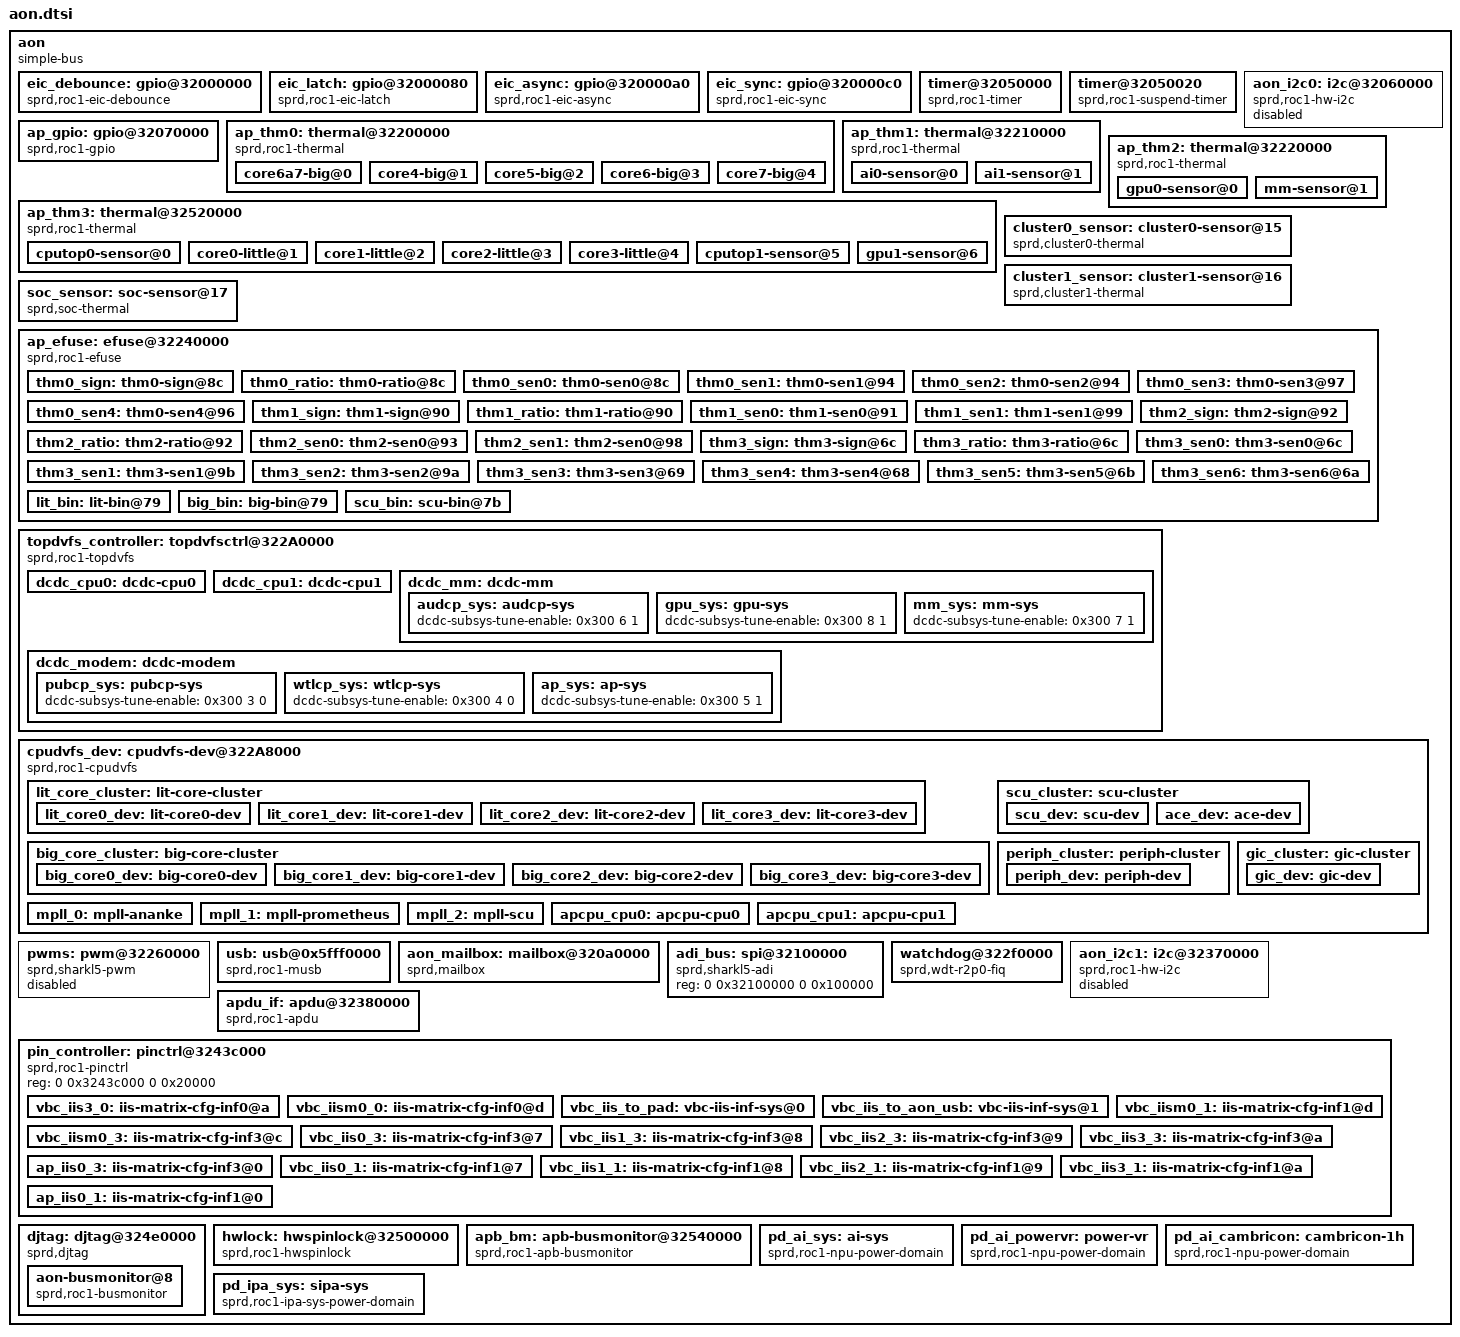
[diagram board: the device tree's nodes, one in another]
/*
 * Spreadtrum Roc1 platform DTS file
 *
 * Copyright (C) 2018, Spreadtrum Communications Inc.
 *
 * This file is licensed under a dual GPLv2 or X11 license.
 */

		aon {
			compatible = "simple-bus";
			#address-cells = <2>;
			#size-cells = <2>;
			ranges;

			eic_debounce: gpio@32000000 {
				compatible = "sprd,roc1-eic-debounce";
				reg = <0 0x32000000 0 0x80>,
				      <0 0x32010000 0 0x80>,
				      <0 0x32020000 0 0x80>,
				      <0 0x32030000 0 0x80>,
				      <0 0x32230000 0 0x80>,
				      <0 0x32270000 0 0x80>;
				gpio-controller;
				#gpio-cells = <2>;
				interrupt-controller;
				#interrupt-cells = <2>;
				interrupts = <GIC_SPI 72 IRQ_TYPE_LEVEL_HIGH>;
			};

			eic_latch: gpio@32000080 {
				compatible = "sprd,roc1-eic-latch";
				reg = <0 0x32000080 0 0x20>,
				      <0 0x32010080 0 0x20>,
				      <0 0x32020080 0 0x20>,
				      <0 0x32030080 0 0x20>,
				      <0 0x32230080 0 0x20>,
				      <0 0x32270080 0 0x20>;
				gpio-controller;
				#gpio-cells = <2>;
				interrupt-controller;
				#interrupt-cells = <2>;
				interrupts = <GIC_SPI 72 IRQ_TYPE_LEVEL_HIGH>;
			};

			eic_async: gpio@320000a0 {
				compatible = "sprd,roc1-eic-async";
				reg = <0 0x320000a0 0 0x20>,
				      <0 0x320100a0 0 0x20>,
				      <0 0x320200a0 0 0x20>,
				      <0 0x320300a0 0 0x20>,
				      <0 0x322300a0 0 0x20>,
				      <0 0x322700a0 0 0x20>;
				gpio-controller;
				#gpio-cells = <2>;
				interrupt-controller;
				#interrupt-cells = <2>;
				interrupts = <GIC_SPI 72 IRQ_TYPE_LEVEL_HIGH>;
			};

			eic_sync: gpio@320000c0 {
				compatible = "sprd,roc1-eic-sync";
				reg = <0 0x320000c0 0 0x20>,
				      <0 0x320100c0 0 0x20>,
				      <0 0x320200c0 0 0x20>,
				      <0 0x320300c0 0 0x20>,
				      <0 0x322300c0 0 0x20>,
				      <0 0x322700c0 0 0x20>;
				gpio-controller;
				#gpio-cells = <2>;
				interrupt-controller;
				#interrupt-cells = <2>;
				interrupts = <GIC_SPI 72 IRQ_TYPE_LEVEL_HIGH>;
			};

			timer@32050000 {
				compatible = "sprd,roc1-timer";
				reg = <0 0x32050000 0 0x20>;
				interrupts = <GIC_SPI 71 IRQ_TYPE_LEVEL_HIGH>;
				clocks = <&ext_32k>;
			};

			timer@32050020 {
				compatible = "sprd,roc1-suspend-timer";
				reg = <0 0x32050020 0 0x20>;
				clocks = <&ext_32k>;
			};

			aon_i2c0: i2c@32060000 {
				compatible = "sprd,roc1-hw-i2c";
				reg = <0 0x32060000 0 0x1000>;
				interrupts = <GIC_SPI 68 IRQ_TYPE_LEVEL_HIGH>;
				clock-names = "source", "enable", "i2c",
						"clk_hw_i2c";
				clock-frequency = <400000>;
				#address-cells = <1>;
				#size-cells = <0>;
				status = "disabled";
			};

			ap_gpio: gpio@32070000 {
				compatible = "sprd,roc1-gpio";
				reg = <0 0x32070000 0 0x10000>;
				gpio-controller;
				#gpio-cells = <2>;
				interrupt-controller;
				#interrupt-cells = <2>;
				interrupts = <GIC_SPI 61 IRQ_TYPE_LEVEL_HIGH>;
			};

			ap_thm0: thermal@32200000 {
				compatible = "sprd,roc1-thermal";
				reg = <0 0x32200000 0 0x10000>;
				clock-names = "enable";
				clocks = <&aonapb_gate CLK_THM0_EB>;
				#thermal-sensor-cells = <1>;
				nvmem-cells = <&thm0_sign>, <&thm0_ratio>;
				nvmem-cell-names = "thm_sign_cal", "thm_ratio_cal";

				core6a7-big@0{
					reg = <0>;
					nvmem-cells = <&thm0_sen0>;
					nvmem-cell-names = "sen_delta_cal";
				};

				core4-big@1{
					reg = <1>;
					nvmem-cells = <&thm0_sen1>;
					nvmem-cell-names = "sen_delta_cal";
				};

				core5-big@2{
					reg = <2>;
					nvmem-cells = <&thm0_sen2>;
					nvmem-cell-names = "sen_delta_cal";
				};

				core6-big@3{
					reg = <3>;
					nvmem-cells = <&thm0_sen3>;
					nvmem-cell-names = "sen_delta_cal";
				};

				core7-big@4{
					reg = <4>;
					nvmem-cells = <&thm0_sen4>;
					nvmem-cell-names = "sen_delta_cal";
				};
			};

			ap_thm1: thermal@32210000 {
				compatible = "sprd,roc1-thermal";
				reg = <0 0x32210000 0 0x10000>;
				clock-names = "enable";
				clocks = <&aonapb_gate CLK_THM1_EB>;
				#thermal-sensor-cells = <1>;
				nvmem-cells = <&thm1_sign>, <&thm1_ratio>;
				nvmem-cell-names = "thm_sign_cal", "thm_ratio_cal";

				ai0-sensor@0{
					reg = <0>;
					nvmem-cells = <&thm1_sen0>;
					nvmem-cell-names = "sen_delta_cal";
				};

				ai1-sensor@1{
					reg = <1>;
					nvmem-cells = <&thm1_sen1>;
					nvmem-cell-names = "sen_delta_cal";
				};
			};

			ap_thm2: thermal@32220000 {
				compatible = "sprd,roc1-thermal";
				reg = <0 0x32220000 0 0x10000>;
				clock-names = "enable";
				clocks = <&aonapb_gate CLK_THM2_EB>;
				#thermal-sensor-cells = <1>;
				nvmem-cells = <&thm2_sign>, <&thm2_ratio>;
				nvmem-cell-names = "thm_sign_cal", "thm_ratio_cal";

				gpu0-sensor@0{
					reg = <0>;
					nvmem-cells = <&thm2_sen0>;
					nvmem-cell-names = "sen_delta_cal";
				};

				mm-sensor@1{
					reg = <1>;
					nvmem-cells = <&thm2_sen1>;
					nvmem-cell-names = "sen_delta_cal";
				};
			};

			ap_thm3: thermal@32520000 {
				compatible = "sprd,roc1-thermal";
				reg = <0 0x32520000 0 0x10000>;
				clock-names = "enable";
				clocks = <&aonapb_gate CLK_THM3_EB>;
				#thermal-sensor-cells = <1>;
				nvmem-cells = <&thm3_sign>, <&thm3_ratio>;
				nvmem-cell-names = "thm_sign_cal", "thm_ratio_cal";

				cputop0-sensor@0{
					reg = <0>;
					nvmem-cells = <&thm3_sen0>;
					nvmem-cell-names = "sen_delta_cal";
				};

				core0-little@1{
					reg = <1>;
					nvmem-cells = <&thm3_sen1>;
					nvmem-cell-names = "sen_delta_cal";
				};

				core1-little@2{
					reg = <2>;
					nvmem-cells = <&thm3_sen2>;
					nvmem-cell-names = "sen_delta_cal";
				};

				core2-little@3{
					reg = <3>;
					nvmem-cells = <&thm3_sen3>;
					nvmem-cell-names = "sen_delta_cal";
				};

				core3-little@4{
					reg = <4>;
					nvmem-cells = <&thm3_sen4>;
					nvmem-cell-names = "sen_delta_cal";
				};

				cputop1-sensor@5{
					reg = <5>;
					nvmem-cells = <&thm3_sen5>;
					nvmem-cell-names = "sen_delta_cal";
				};

				gpu1-sensor@6{
					reg = <6>;
					nvmem-cells = <&thm3_sen6>;
					nvmem-cell-names = "sen_delta_cal";
				};
			};

			cluster0_sensor: cluster0-sensor@15 {
				compatible = "sprd,cluster0-thermal";
				#thermal-sensor-cells = <1>;
				sensor-names = "littlecore0-thmzone",
					"littlecore1-thmzone",
					"littlecore2-thmzone",
					"littlecore3-thmzone";
				k-po = <128>;
				k-pu = <256>;
				k-i = <2>;
				k-d = <0>;
				cutoff = <10000>;
			};

			cluster1_sensor: cluster1-sensor@16 {
				compatible = "sprd,cluster1-thermal";
				#thermal-sensor-cells = <1>;
				sensor-names = "bigcore4-thmzone",
					"bigcore5-thmzone",
					"bigcore6-thmzone",
					"bigcore7-thmzone";
				k-po = <128>;
				k-pu = <256>;
				k-i = <2>;
				k-d = <0>;
				cutoff = <10000>;
			};

			soc_sensor: soc-sensor@17 {
				compatible = "sprd,soc-thermal";
				#thermal-sensor-cells = <1>;
				sensor-names = "cluster0-thmzone",
					"cluster1-thmzone";
				k-po = <0>;
				k-pu = <0>;
				k-i = <2>;
				k-d = <0>;
				cutoff = <0>;
			};

			ap_efuse: efuse@32240000 {
				compatible = "sprd,roc1-efuse";
				reg = <0 0x32240000 0 0x10000>;
				clock-names = "enable";
				hwlocks = <&hwlock 8>;
				clocks = <&aonapb_gate CLK_EFUSE_EB>;

				thm0_sign: thm0-sign@8c{
					reg = <0x8c 0x4>;
					bits = <0 1>;
				};

				thm0_ratio: thm0-ratio@8c{
					reg = <0x8c 0x4>;
					bits = <1 7>;
				};

				thm0_sen0: thm0-sen0@8c{
					reg = <0x8d 0x4>;
					bits = <0 8>;
				};

				thm0_sen1: thm0-sen1@94{
					reg = <0x95 0x4>;
					bits = <0 8>;
				};

				thm0_sen2: thm0-sen2@94{
					reg = <0x94 0x4>;
					bits = <0 8>;
				};

				thm0_sen3: thm0-sen3@97{
					reg = <0x97 0x4>;
					bits = <0 8>;
				};

				thm0_sen4: thm0-sen4@96{
					reg = <0x96 0x4>;
					bits = <0 8>;
				};

				thm1_sign: thm1-sign@90{
					reg = <0x90 0x4>;
					bits = <0 1>;
				};

				thm1_ratio: thm1-ratio@90{
					reg = <0x90 0x4>;
					bits = <1 7>;
				};

				thm1_sen0: thm1-sen0@91{
					reg = <0x91 0x4>;
					bits = <0 8>;
				};

				thm1_sen1: thm1-sen1@99{
					reg = <0x99 0x4>;
					bits = <0 8>;
				};

				thm2_sign: thm2-sign@92{
					reg = <0x92 0x4>;
					bits = <0 1>;
				};

				thm2_ratio: thm2-ratio@92{
					reg = <0x92 0x4>;
					bits = <1 7>;
				};

				thm2_sen0: thm2-sen0@93{
					reg = <0x93 0x4>;
					bits = <0 8>;
				};

				thm2_sen1: thm2-sen0@98{
					reg = <0x98 0x4>;
					bits = <0 8>;
				};

				thm3_sign: thm3-sign@6c{
					reg = <0x6c 0x4>;
					bits = <0 1>;
				};

				thm3_ratio: thm3-ratio@6c{
					reg = <0x6c 0x4>;
					bits = <1 7>;
				};

				thm3_sen0: thm3-sen0@6c{
					reg = <0x6d 0x4>;
					bits = <0 8>;
				};

				thm3_sen1: thm3-sen1@9b{
					reg = <0x9b 0x4>;
					bits = <0 8>;
				};

				thm3_sen2: thm3-sen2@9a{
					reg = <0x9a 0x4>;
					bits = <0 8>;
				};

				thm3_sen3: thm3-sen3@69{
					reg = <0x69 0x4>;
					bits = <0 8>;
				};

				thm3_sen4: thm3-sen4@68{
					reg = <0x68 0x4>;
					bits = <0 8>;
				};

				thm3_sen5: thm3-sen5@6b{
					reg = <0x6b 0x4>;
					bits = <0 8>;
				};

				thm3_sen6: thm3-sen6@6a{
					reg = <0x6a 0x4>;
					bits = <0 8>;
				};

				lit_bin: lit-bin@79{
					reg = <0x79 0x1>;
					bits = <0 4>;
				};

				big_bin: big-bin@79{
					reg = <0x79 0x1>;
					bits = <4 4>;
				};

				scu_bin: scu-bin@7b{
					reg = <0x7b 0x1>;
					bits = <4 4>;
				};
			};

			topdvfs_controller: topdvfsctrl@322A0000 {
				compatible = "sprd,roc1-topdvfs", "syscon";
				sprd,syscon-enable = <&aon_apb_regs>;
				module-enable-cfg = <0x4 7>;
				reg = <0 0x322A0000 0 0x8000>;
				cpu-dcdc-cells = <&dcdc_cpu0>, <&dcdc_cpu1>;
				device-dcdc-cells = <&dcdc_mm>, <&dcdc_modem>;
				dcdc_cpu0: dcdc-cpu0{
					dcdc-dvfs-enable = <0x90 0 1>;
					dcdc-judge-vol-sw = <0x150 15 0x7 0>;
					dcdc-subsys-tune-enable = <0x300 2 1>;
					dcdc-supply-mode-cfg = <&dvfs_dcdc_cpu0_supply>;
					sync-dcdc-idle-voltage;
					dcdc-idle-voltage = <0x320 6 0x7 5>;
				};
				dcdc_cpu1: dcdc-cpu1{
					dcdc-dvfs-enable = <0xA0 0 1>;
					dcdc-judge-vol-sw = <0x160 15 0x7 0>;
					dcdc-subsys-tune-enable = <0x300 1 1>;
					dcdc-supply-mode-cfg = <&dvfs_dcdc_cpu1_supply>;
					sync-dcdc-idle-voltage;
					dcdc-idle-voltage = <0x320 3 0x7 5>;
				};
				dcdc_mm: dcdc-mm {
					dcdc-dvfs-enable = <0x18 20 1>;
					dcdc-judge-vol-sw = <0x18 1 0x7 2>;
					dcdc-subsys-cells = <&audcp_sys>,
							<&gpu_sys>,
							<&mm_sys>;
					audcp_sys: audcp-sys {
						dcdc-subsys-tune-enable = <0x300 6 1>;
					};
					gpu_sys: gpu-sys {
						dcdc-subsys-tune-enable = <0x300 8 1>;
					};

					mm_sys: mm-sys {
						dcdc-subsys-tune-enable = <0x300 7 1>;
					};
				};
				dcdc_modem: dcdc-modem {
					dcdc-dvfs-enable = <0x48 20 1>;
					dcdc-judge-vol-sw = <0x48 1 0x7 2>;
					dcdc-subsys-cells = <&pubcp_sys>,
							<&wtlcp_sys>,
							<&ap_sys>;
					pubcp_sys: pubcp-sys {
						dcdc-subsys-tune-enable = <0x300 3 0>;
					};
					wtlcp_sys: wtlcp-sys {
						dcdc-subsys-tune-enable = <0x300 4 0>;
					};
					ap_sys: ap-sys {
						dcdc-subsys-tune-enable = <0x300 5 1>;
					};
				};
			};

			cpudvfs_dev: cpudvfs-dev@322A8000 {
				compatible = "sprd,roc1-cpudvfs";
				sprd,syscon-enable = <&aon_apb_regs>;
				module-enable-cfg = <0x4 7>;
				topdvfs-controller = <&topdvfs_controller>;
				reg = <0 0x322A8000 0 0x1000>;
				mpll-cells = <&mpll_0>, <&mpll_1>, <&mpll_2>;
				apcpu-dvfs-dcdc-cells = <&apcpu_cpu0>,
						<&apcpu_cpu1>;
				cpudvfs-clusters = <&lit_core_cluster>,
						<&big_core_cluster>,
						<&scu_cluster>,
						<&periph_cluster>,
						<&gic_cluster>;
				lit_core_cluster: lit-core-cluster {
					cluster-name = "lit-core-cluster";
					row-num = <16>;
					column-num = <7>;
					work-index-cfg = <0x214 0xF>;
					idle-index-cfg = <0x218 0xF>;
					tuning-latency-us = <200>;
					tuning-result-judge = <0>;
					dcdc-name = "DCDC_CPU0";
					map-tbl-regs = <0x60 0x64 0x68 0x6C 0x70 0x74 0x78 0x7C 0x80 0x84 0x88 0x8C 0x90 0x94 0x98 0x9C>;
					column-entry-start-bit = <0 2 15 5 9 18 12>;
					column-entry-mask = <0x3 0x7 0x7 0xF 0x7 0x7 0x7>;
					cluster-devices = <&lit_core0_dev>,
							<&lit_core1_dev>,
							<&lit_core2_dev>,
							<&lit_core3_dev>;
					lit-core-dvfs-tbl = < /* od */
							/* sel div gear scu periph gic mpll */
							0 0 0 0 0 0 0
							2 1 0 1 1 1 0
							1 0 0 1 1 1 0
							3 0 1 2 1 1 0
							3 0 2 3 2 2 1
							2 0 3 4 2 2 0
							3 0 4 5 2 3 2
							3 0 5 6 2 3 3
							3 0 6 7 2 3 4
							3 0 7 8 2 3 5
							3 0 7 8 2 3 5
							3 0 7 8 2 3 5
							3 0 7 8 2 3 5
							3 0 7 8 2 3 5
							3 0 7 8 2 3 5
							3 0 7 8 2 3 5
							>;
					lit-core-dvfs-tbl-1 = <
							/* sel div gear scu periph gic mpll */
							0 0 0 0 0 0 0
							2 1 0 1 1 1 0
							1 0 0 1 1 1 0
							3 0 0 2 1 1 0
							3 0 0 3 2 2 1
							2 0 1 4 2 2 0
							3 0 2 5 2 3 2
							3 0 3 6 2 3 3
							3 0 4 7 2 3 4
							3 0 5 8 2 3 5
							3 0 5 8 2 3 5
							3 0 5 8 2 3 5
							3 0 5 8 2 3 5
							3 0 5 8 2 3 5
							3 0 5 8 2 3 5
							3 0 5 8 2 3 5
							>;
					lit-core-dvfs-tbl-2 = <
							/* sel div gear scu periph gic mpll */
							0 0 0 0 0 0 0
							2 1 0 1 1 1 0
							1 0 0 1 1 1 0
							3 0 0 2 1 1 0
							3 0 1 3 2 2 1
							2 0 2 4 2 2 0
							3 0 3 5 2 3 2
							3 0 4 6 2 3 3
							3 0 5 7 2 3 4
							3 0 6 8 2 3 5
							3 0 6 8 2 3 5
							3 0 6 8 2 3 5
							3 0 6 8 2 3 5
							3 0 6 8 2 3 5
							3 0 6 8 2 3 5
							3 0 6 8 2 3 5
							>;
					lit-core-dvfs-tbl-3 = <
							/* sel div gear scu periph gic mpll */
							0 0 0 0 0 0 0
							2 1 0 1 1 1 0
							1 0 0 1 1 1 0
							3 0 0 2 1 1 0
							3 0 1 3 2 2 1
							2 0 2 4 2 2 0
							3 0 3 5 2 3 2
							3 0 4 6 2 3 3
							3 0 5 7 2 3 4
							3 0 6 8 2 3 5
							3 0 6 8 2 3 5
							3 0 6 8 2 3 5
							3 0 6 8 2 3 5
							3 0 6 8 2 3 5
							3 0 6 8 2 3 5
							3 0 6 8 2 3 5
							>;
					lit-core-dvfs-tbl-4 = <
							/* sel div gear scu periph gic mpll */
							0 0 0 0 0 0 0
							2 1 0 1 1 1 0
							1 0 0 1 1 1 0
							3 0 1 2 1 1 0
							3 0 2 3 2 2 1
							2 0 3 4 2 2 0
							3 0 4 5 2 3 2
							3 0 5 6 2 3 3
							3 0 6 7 2 3 4
							3 0 7 8 2 3 5
							3 0 7 8 2 3 5
							3 0 7 8 2 3 5
							3 0 7 8 2 3 5
							3 0 7 8 2 3 5
							3 0 7 8 2 3 5
							3 0 7 8 2 3 5
							>;
					lit_core0_dev: lit-core0-dev {
						device-name = "cpu0";
						sel-get = <0x38 0 3>;
						div-get = <0x38 2 7>;
						vol-get = <0x30 0 7>;
						dfs-idle-disable = <0x308 0 1>;
					};
					lit_core1_dev: lit-core1-dev {
						device-name = "cpu1";
						sel-get = <0x38 5 3>;
						div-get = <0x38 7 7>;
						vol-get = <0x30 3 7>;
						dfs-idle-disable = <0x308 1 1>;
					};
					lit_core2_dev: lit-core2-dev {
						device-name = "cpu2";
						sel-get = <0x38 10 3>;
						div-get = <0x38 12 7>;
						vol-get = <0x30 6 7>;
						dfs-idle-disable = <0x308 2 1>;
					};
					lit_core3_dev: lit-core3-dev {
						device-name = "cpu3";
						sel-get = <0x38 15 3>;
						div-get = <0x38 17 7>;
						vol-get = <0x30 9 7>;
						dfs-idle-disable = <0x308 3 1>;
					};
				};
				big_core_cluster: big-core-cluster {
					cluster-name = "big-core-cluster";
					row-num = <16>;
					column-num = <8>;
					work-index-cfg = <0x224 0xF>;
					idle-index-cfg = <0x228 0xF>;
					tuning-latency-us = <200>;
					tuning-result-judge = <0>;
					dcdc-name = "DCDC_CPU1";
					map-tbl-regs = <0xA0 0xA4 0xA8 0xAC 0xB0 0xB4 0xB8 0xBC 0xC0 0xC4 0xC8 0xCC 0xD0 0xD4 0xD8 0xDC>;
					column-entry-start-bit = <0 2 15 5 9 18 12 21>;
					column-entry-mask = <0x3 0x7 0x7 0xF 0x7 0x7 0x7 0x7>;
					cluster-devices = <&big_core0_dev>,
							<&big_core1_dev>,
							<&big_core2_dev>,
							<&big_core3_dev>;
					big-core-dvfs-tbl = < /* od */
							/* sel div gear scu periph cpu0 mpll gic */
							0 0 0 0 0 0 0 0
							1 0 0 3 2 0 0 2
							3 0 1 5 2 0 0 3
							3 0 2 7 2 0 1 3
							3 0 3 8 2 0 2 3
							3 0 4 8 2 0 3 3
							3 0 5 8 2 0 4 3
							3 0 5 8 2 0 4 3
							3 0 5 8 2 0 4 3
							3 0 5 8 2 0 4 3
							3 0 5 8 2 0 4 3
							3 0 5 8 2 0 4 3
							3 0 5 8 2 0 4 3
							3 0 5 8 2 0 4 3
							3 0 5 8 2 0 4 3
							3 0 5 8 2 0 4 3
							>;
					big-core-dvfs-tbl-1 = <
							/* sel div gear scu periph cpu0 mpll gic */
							0 0 0 0 0 0 0 0
							1 0 0 3 2 0 0 2
							3 0 1 5 2 0 0 3
							3 0 2 7 2 0 1 3
							3 0 3 8 2 0 2 3
							3 0 4 8 2 0 3 3
							3 0 5 8 2 0 4 3
							3 0 5 8 2 0 4 3
							3 0 5 8 2 0 4 3
							3 0 5 8 2 0 4 3
							3 0 5 8 2 0 4 3
							3 0 5 8 2 0 4 3
							3 0 5 8 2 0 4 3
							3 0 5 8 2 0 4 3
							3 0 5 8 2 0 4 3
							3 0 5 8 2 0 4 3
							>;
					big-core-dvfs-tbl-2 = <
							/* sel div gear scu periph cpu0 mpll gic */
							0 0 0 0 0 0 0 0
							1 0 0 3 2 0 0 2
							3 0 1 5 2 0 0 3
							3 0 2 7 2 0 1 3
							3 0 3 8 2 0 2 3
							3 0 4 8 2 0 3 3
							3 0 5 8 2 0 4 3
							3 0 5 8 2 0 4 3
							3 0 5 8 2 0 4 3
							3 0 5 8 2 0 4 3
							3 0 5 8 2 0 4 3
							3 0 5 8 2 0 4 3
							3 0 5 8 2 0 4 3
							3 0 5 8 2 0 4 3
							3 0 5 8 2 0 4 3
							3 0 5 8 2 0 4 3
							>;
					big-core-dvfs-tbl-3 = <
							/* sel div gear scu periph cpu0 mpll gic */
							0 0 0 0 0 0 0 0
							1 0 0 3 2 0 0 2
							3 0 1 5 2 0 0 3
							3 0 2 7 2 0 1 3
							3 0 3 8 2 0 2 3
							3 0 4 8 2 0 3 3
							3 0 5 8 2 0 4 3
							3 0 5 8 2 0 4 3
							3 0 5 8 2 0 4 3
							3 0 5 8 2 0 4 3
							3 0 5 8 2 0 4 3
							3 0 5 8 2 0 4 3
							3 0 5 8 2 0 4 3
							3 0 5 8 2 0 4 3
							3 0 5 8 2 0 4 3
							3 0 5 8 2 0 4 3
							>;
					big-core-dvfs-tbl-4 = <
							/* sel div gear scu periph cpu0 mpll gic */
							0 0 0 0 0 0 0 0
							1 0 0 3 2 0 0 2
							3 0 1 5 2 0 0 3
							3 0 2 7 2 0 1 3
							3 0 3 8 2 0 2 3
							3 0 4 8 2 0 3 3
							3 0 5 8 2 0 4 3
							3 0 5 8 2 0 4 3
							3 0 5 8 2 0 4 3
							3 0 5 8 2 0 4 3
							3 0 5 8 2 0 4 3
							3 0 5 8 2 0 4 3
							3 0 5 8 2 0 4 3
							3 0 5 8 2 0 4 3
							3 0 5 8 2 0 4 3
							3 0 5 8 2 0 4 3
							>;
					big_core0_dev: big-core0-dev {
						device-name = "cpu4";
						sel-get = <0x38 20 3>;
						div-get = <0x38 22 7>;
						vol-get = <0x30 12 7>;
						dfs-idle-disable = <0x308 4 1>;
					};
					big_core1_dev: big-core1-dev {
						device-name = "cpu5";
						sel-get = <0x38 25 3>;
						div-get = <0x38 27 7>;
						vol-get = <0x30 15 7>;
						dfs-idle-disable = <0x308 5 1>;
					};
					big_core2_dev: big-core2-dev {
						device-name = "cpu6";
						sel-get = <0x3C 0 3>;
						div-get = <0x3C 2 7>;
						vol-get = <0x30 18 7>;
						dfs-idle-disable = <0x308 6 1>;
					};
					big_core3_dev: big-core3-dev {
						device-name = "cpu7";
						sel-get = <0x3C 5 3>;
						div-get = <0x3C 7 7>;
						vol-get = <0x30 21 7>;
						dfs-idle-disable = <0x308 7 1>;
					};
				};
				scu_cluster: scu-cluster {
					cluster-name = "scu-cluster";
					row-num = <16>;
					column-num = <5>;
					work-index-cfg = <0x22C 0xF>;
					idle-index-cfg = <0x230 0xF>;
					dcdc-name = "DCDC_CPU0";
					tuning-func-cfg = <0x18 1>;
					map-tbl-regs = <0x180 0x184 0x188 0x18C 0x190 0x194 0x198 0x19C 0x1A0 0x1A4 0x1A8 0x1AC 0x1B0 0x1B4 0x1B8 0x1BC>;
					column-entry-start-bit = <0 3 12 6 9>;
					column-entry-mask = <0x7 0x7 0x7 0x7 0x7>;
					cluster-devices = <&scu_dev>, <&ace_dev>;
					scu-dvfs-tbl = <
							/* sel div gear ace mpll */
							0 0 0 0 0
							4 0 0 1 0
							4 0 1 1 1
							1 0 2 1 0
							4 0 3 1 2
							4 0 4 1 3
							4 0 5 1 3
							4 0 6 1 4
							4 0 7 1 5
							4 0 7 1 5
							4 0 7 1 5
							4 0 7 1 5
							4 0 7 1 5
							4 0 7 1 5
							4 0 7 1 5
							4 0 7 1 5
							>;
					scu-dvfs-tbl-1 = <
							/* sel div gear ace mpll */
							0 0 0 0 0
							4 0 0 1 0
							4 0 0 1 1
							1 0 0 1 0
							4 0 1 1 2
							4 0 2 1 3
							4 0 3 1 3
							4 0 4 1 4
							4 0 5 1 5
							4 0 5 1 5
							4 0 5 1 5
							4 0 5 1 5
							4 0 5 1 5
							4 0 5 1 5
							4 0 5 1 5
							4 0 5 1 5
							>;
					scu-dvfs-tbl-2 = <
							/* sel div gear ace mpll */
							0 0 0 0 0
							4 0 0 1 0
							4 0 0 1 1
							1 0 1 1 0
							4 0 2 1 2
							4 0 3 1 3
							4 0 4 1 3
							4 0 5 1 4
							4 0 6 1 5
							4 0 6 1 5
							4 0 6 1 5
							4 0 6 1 5
							4 0 6 1 5
							4 0 6 1 5
							4 0 6 1 5
							4 0 6 1 5
							>;
					scu-dvfs-tbl-3 = <
							/* sel div gear ace mpll */
							0 0 0 0 0
							4 0 0 1 0
							4 0 0 1 1
							1 0 1 1 0
							4 0 2 1 2
							4 0 3 1 3
							4 0 4 1 3
							4 0 5 1 4
							4 0 6 1 5
							4 0 6 1 5
							4 0 6 1 5
							4 0 6 1 5
							4 0 6 1 5
							4 0 6 1 5
							4 0 6 1 5
							4 0 6 1 5
							>;
					scu-dvfs-tbl-4 = <
							/* sel div gear ace mpll */
							0 0 0 0 0
							4 0 0 1 0
							4 0 1 1 1
							1 0 2 1 0
							4 0 3 1 2
							4 0 4 1 3
							4 0 5 1 3
							4 0 6 1 4
							4 0 7 1 5
							4 0 7 1 5
							4 0 7 1 5
							4 0 7 1 5
							4 0 7 1 5
							4 0 7 1 5
							4 0 7 1 5
							4 0 7 1 5
							>;
					scu_dev: scu-dev {
						device-name = "scu";
						sel-get = <0x3C 10 7>;
						div-get = <0x3C 13 7>;
						vol-get = <0x34 0 7>;
						dfs-idle-disable = <0x308 8 1>;
					};
					ace_dev: ace-dev {
						device-name = "ace";
						sel-get = <0x3C 10 7>;
						div-get = <0x3C 16 7>;
						vol-get = <0x34 0 7>;
					};
				};
				periph_cluster: periph-cluster {
					cluster-name = "periph-cluster";
					row-num = <8>;
					column-num = <3>;
					work-index-cfg = <0x23C 0x7>;
					idle-index-cfg = <0x240 0x7>;
					dcdc-name = "DCDC_CPU0";
					tuning-func-cfg = <0x18 0>;
					map-tbl-regs = <0x1F4 0x1F8 0x1FC 0x200 0x204 0x208 0x20C 0x210>;
					column-entry-start-bit = <0 2 5>;
					column-entry-mask = <0x3 0x7 0x7>;
					cluster-devices = <&periph_dev>;
					periph-dvfs-tbl = <
							/* sel div vol */
							0 0 0
							1 0 0
							2 1 2
							2 1 2
							2 1 2
							2 1 2
							2 1 2
							2 1 2
							>;
					periph-dvfs-tbl-1 = <
							/* sel div vol */
							0 0 0
							1 0 0
							2 1 0
							2 1 0
							2 1 0
							2 1 0
							2 1 0
							2 1 0
							>;
					periph-dvfs-tbl-2 = <
							/* sel div vol */
							0 0 0
							1 0 0
							2 1 1
							2 1 1
							2 1 1
							2 1 1
							2 1 1
							2 1 1
							>;
					periph-dvfs-tbl-3 = <
							/* sel div vol */
							0 0 0
							1 0 0
							2 1 1
							2 1 1
							2 1 1
							2 1 1
							2 1 1
							2 1 1
							>;
					periph-dvfs-tbl-4 = <
							/* sel div vol */
							0 0 0
							1 0 0
							2 1 2
							2 1 2
							2 1 2
							2 1 2
							2 1 2
							2 1 2
							>;
					periph_dev: periph-dev {
						device-name = "periph";
						sel-get = <0x3C 19 3>;
						div-get = <0x3C 21 7>;
						vol-get = <0x34 6 7>;
						dfs-idle-disable = <0x308 10 1>;
					};
				};

				gic_cluster: gic-cluster {
					cluster-name = "gic-cluster";
					row-num = <8>;
					column-num = <3>;
					work-index-cfg = <0x2E0 0x7>;
					idle-index-cfg = <0x2E4 0x7>;
					dcdc-name = "DCDC_CPU0";
					tuning-func-cfg = <0x18 2>;
					map-tbl-regs = <0x280 0x284 0x288 0x28C 0x290 0x294 0x298 0x29C>;
					column-entry-start-bit = <0 2 5>;
					column-entry-mask = <0x3 0x7 0x7>;
					cluster-devices = <&gic_dev>;
					gic-dvfs-tbl = <
							/* sel div vol */
							0 0 0
							1 0 0
							2 1 2
							3 1 4
							3 1 4
							3 1 4
							3 1 4
							3 1 4
							>;
					gic-dvfs-tbl-1 = <
							/* sel div vol */
							0 0 0
							1 0 0
							2 1 0
							3 1 2
							3 1 2
							3 1 2
							3 1 2
							3 1 2
							>;
					gic-dvfs-tbl-2 = <
							/* sel div vol */
							0 0 0
							1 0 0
							2 1 1
							3 1 3
							3 1 3
							3 1 3
							3 1 3
							3 1 3
							>;
					gic-dvfs-tbl-3 = <
							/* sel div vol */
							0 0 0
							1 0 0
							2 1 1
							3 1 3
							3 1 3
							3 1 3
							3 1 3
							3 1 3
							>;
					gic-dvfs-tbl-4 = <
							/* sel div vol */
							0 0 0
							1 0 0
							2 1 2
							3 1 4
							3 1 4
							3 1 4
							3 1 4
							3 1 4
							>;
					gic_dev: gic-dev {
						device-name = "gic";
						sel-get = <0x40 0 3>;
						div-get = <0x40 2 7>;
						vol-get = <0x34 9 7>;
						dfs-idle-disable = <0x308 11 1>;
					};
				};

				mpll_0: mpll-ananke{
					sprd,syscon-ang = <&anlg_phy_g17_regs>;
					mpll-rst = <0x44 0 1 2>;
					relock-cfg = <0x244 1>;
					pd-cfg = <0x244 0>;
				};

				mpll_1: mpll-prometheus{
					sprd,syscon-ang = <&anlg_phy_g4_regs>;
					mpll-rst = <0x40 2 4 3>;
					relock-cfg = <0x258 1>;
					pd-cfg = <0x258 0>;
				};

				mpll_2: mpll-scu{
					sprd,syscon-ang = <&anlg_phy_g9_regs>;
					mpll-rst = <0x40 0 1 2>;
					relock-cfg = <0x26C 1>;
					pd-cfg = <0x26C 0>;
				};

				apcpu_cpu0: apcpu-cpu0 {
					subsys-dcdc-vol-sw = <0x20 4 0x7 0>;
					subsys-dvfs-state = <0x44 0 7>;
				};
				apcpu_cpu1: apcpu-cpu1 {
					subsys-dcdc-vol-sw = <0x24 4 0x7 0>;
					subsys-dvfs-state = <0x4C 0 7>;
				};
			};

			pwms: pwm@32260000 {
				compatible = "sprd,sharkl5-pwm", "sprd,roc1-pwm";
				reg = <0 0x32260000 0 0x10000>;
				status = "disabled";
				clock-names = "clk_parent",
					"clk_pwm0", "clk_pwm0_eb",
					"clk_pwm1", "clk_pwm1_eb",
					"clk_pwm2", "clk_pwm2_eb",
					"clk_pwm3", "clk_pwm3_eb";
				clocks = <&ext_26m>,
					<&aon_clk CLK_AON_PWM0>,
					<&aonapb_gate CLK_PWM0_EB>,
					<&aon_clk CLK_AON_PWM1>,
					<&aonapb_gate CLK_PWM1_EB>,
					<&aon_clk CLK_AON_PWM2>,
					<&aonapb_gate CLK_PWM2_EB>,
					<&aon_clk CLK_AON_PWM3>,
					<&aonapb_gate CLK_PWM3_EB>;
				#pwm-cells = <2>;
			};

			usb: usb@0x5fff0000 {
				compatible = "sprd,roc1-musb";
				reg = <0 0x5fff0000 0 0x2000>;
				interrupts = <GIC_SPI 69 IRQ_TYPE_LEVEL_HIGH>;
				interrupt-names = "mc";
				clocks = <&aonapb_gate CLK_OTG_UTMI_EB>;
				clock-names = "core_clk";
				usb-phy = <&hsphy>;
				phy-names = "usb";
				dr-mode = "peripheral";
			};

			aon_mailbox: mailbox@320a0000 {
				compatible = "sprd,mailbox";
				reg = <0 0x320a0000 0 0x8000>,
				      <0 0x320a8000 0 0x8000>;
				syscons = <&aon_apb_regs 0x4 0x4>;
				syscon-names = "clk";
				interrupts = <GIC_SPI 82 IRQ_TYPE_LEVEL_HIGH>,
					     <GIC_SPI 83 IRQ_TYPE_LEVEL_HIGH>,
					     <GIC_SPI 84 IRQ_TYPE_LEVEL_HIGH>;
				sprd,sensor = <6>;
				sprd,core-cnt = <7>;
				sprd,version = <3>;
			};

			adi_bus: spi@32100000 {
				compatible = "sprd,sharkl5-adi", "sprd,roc1-adi";
				reg = <0 0x32100000 0 0x100000>;
				#address-cells = <1>;
				#size-cells = <0>;
			};

			watchdog@322f0000 {
				compatible = "sprd,wdt-r2p0-fiq";
				reg = <0 0x322f0000 0 0x10000>;
				interrupts = <GIC_SPI 79 IRQ_TYPE_LEVEL_HIGH>;
				timeout-sec = <12>;
				clock-names = "enable", "rtc_enable";
				clocks = <&aonapb_gate CLK_APCPU_WDG_EB>,
					<&aonapb_gate CLK_AC_WDG_RTC_EB>;
			};

			aon_i2c1: i2c@32370000 {
				compatible = "sprd,roc1-hw-i2c";
				reg = <0 0x32370000 0 0x1000>;
				interrupts = <GIC_SPI 131 IRQ_TYPE_LEVEL_HIGH>;
				clock-names = "source", "enable", "i2c",
						"clk_hw_i2c";
				clock-frequency = <400000>;
				#address-cells = <1>;
				#size-cells = <0>;
				status = "disabled";
			};

			apdu_if: apdu@32380000 {
				compatible = "sprd,roc1-apdu";
				reg = <0 0x32380000 0 0x10000>;
				interrupts = <GIC_SPI 187 IRQ_TYPE_LEVEL_HIGH>;
			};

			pin_controller: pinctrl@3243c000 {
				compatible = "sprd,roc1-pinctrl";
				reg = <0 0x3243c000 0 0x20000>;

				vbc_iis3_0: iis-matrix-cfg-inf0@a {
					pins = "ROC1_IIS_INF0_SYS_SEL";
					sprd,control = <0xa>;
				};

				vbc_iism0_0: iis-matrix-cfg-inf0@d {
					pins = "ROC1_IIS_INF0_SYS_SEL";
					sprd,control = <0xd>;
				};

				vbc_iis_to_pad: vbc-iis-inf-sys@0 {
					pins = "ROC1_VBC_IIS_INF_SYS_SEL";
					sprd,control = <0x0>;
				};

				vbc_iis_to_aon_usb: vbc-iis-inf-sys@1 {
					pins = "ROC1_VBC_IIS_INF_SYS_SEL";
					sprd,control = <0x1>;
				};

				vbc_iism0_1: iis-matrix-cfg-inf1@d {
					pins = "ROC1_IIS_INF1_SYS_SEL";
					sprd,control = <0xd>;
				};

				vbc_iism0_3: iis-matrix-cfg-inf3@c {
					pins = "ROC1_IIS_INF3_SYS_SEL";
					sprd,control = <0xc>;
				};

				vbc_iis0_3: iis-matrix-cfg-inf3@7 {
					pins = "ROC1_IIS_INF3_SYS_SEL";
					sprd,control = <0x7>;
				};

				vbc_iis1_3: iis-matrix-cfg-inf3@8 {
					pins = "ROC1_IIS_INF3_SYS_SEL";
					sprd,control = <0x8>;
				};

				vbc_iis2_3: iis-matrix-cfg-inf3@9 {
					pins = "ROC1_IIS_INF3_SYS_SEL";
					sprd,control = <0x9>;
				};

				vbc_iis3_3: iis-matrix-cfg-inf3@a {
					pins = "ROC1_IIS_INF3_SYS_SEL";
					sprd,control = <0xa>;
				};

				ap_iis0_3: iis-matrix-cfg-inf3@0 {
					pins = "ROC1_IIS_INF3_SYS_SEL";
					sprd,control = <0x0>;
				};

				vbc_iis0_1: iis-matrix-cfg-inf1@7 {
					pins = "ROC1_IIS_INF1_SYS_SEL";
					sprd,control = <0x7>;
				};

				vbc_iis1_1: iis-matrix-cfg-inf1@8 {
					pins = "ROC1_IIS_INF1_SYS_SEL";
					sprd,control = <0x8>;
				};

				vbc_iis2_1: iis-matrix-cfg-inf1@9 {
					pins = "ROC1_IIS_INF1_SYS_SEL";
					sprd,control = <0x9>;
				};

				vbc_iis3_1: iis-matrix-cfg-inf1@a {
					pins = "ROC1_IIS_INF1_SYS_SEL";
					sprd,control = <0xa>;
				};

				ap_iis0_1: iis-matrix-cfg-inf1@0 {
					pins = "ROC1_IIS_INF1_SYS_SEL";
					sprd,control = <0x0>;
				};
			};

			djtag: djtag@324e0000 {
				compatible = "sprd,djtag";
				reg = <0 0x324e0000 0 0x1000>;
				syscon-names = "soft_rst";
				syscons = <&aon_apb_regs REG_AON_APB_APB_RST3
					MASK_AON_APB_DJTAG_SOFT_RST>;
				clock-names = "enable", "tck";
				clocks = <&aonapb_gate CLK_DJTAG_EB>,
					<&aonapb_gate CLK_DJTAG_TCK_EB>;
				hwlocks = <&hwlock 10>;
				hwlock-names = "djtag";

				#address-cells = <1>;
				#size-cells = <0>;

				aon-busmonitor@8{
					compatible  = "sprd,roc1-busmonitor";
					interrupts = <GIC_SPI 81
						IRQ_TYPE_LEVEL_HIGH>;
					reg = <0x8>;
					sprd,bm-num = <6>;
					sprd,bm-name =
						"AP", "WTLCP", "AUDCP", "PUBCP",
						"USBOTG", "CM4";
					sprd,bm-type =
						<AXI>, <AXI>, <AXI>,
						<AXI>, <AXI>, <AXI>;
					sprd,bm-dap = <0>, <1>, <2>, <3>,
						<4>, <5>;
					sprd,bm-config =
						<ENABLE MON_WRITE MON_INSIDE>,
						<ENABLE MON_WRITE MON_INSIDE>,
						<ENABLE MON_WRITE MON_INSIDE>,
						<ENABLE MON_WRITE MON_INSIDE>,
						<DISABLE MON_WRITE MON_INSIDE>,
						<ENABLE MON_WRITE MON_INSIDE>;
					sprd,bm-id =
						<DISABLE 0 AXIID>,
						<DISABLE 0 AXIID>,
						<DISABLE 0 AXIID>,
						<DISABLE 0 AXIID>,
						<DISABLE 0 AXIID>,
						<DISABLE 0 AXIID>;
					sprd,bm-ranges =
						<0x5ffe0000 0x5ffe0018>,
						<0x5ffe0000 0x5ffe0018>,
						<0x5ffe0000 0x5ffe0018>,
						<0x0ffe0000 0x0ffe0018>,
						<0 0>,
						<0x5ffe0000 0x5ffe0018>;
				};
			};

			hwlock: hwspinlock@32500000 {
				compatible = "sprd,roc1-hwspinlock";
				reg = <0 0x32500000 0 0x10000>;
				#hwlock-cells = <1>;
				clock-names = "enable";
				clocks = <&aonapb_gate CLK_SPLK_EB>;
			};

			apb_bm: apb-busmonitor@32540000 {
				compatible = "sprd,roc1-apb-busmonitor";
				reg = <0 0x32540000 0 0x1000>;
				interrupts = <GIC_SPI 102 IRQ_TYPE_LEVEL_HIGH>;
				sprd,target-addr = <0 0>;
				sprd,target-data = <0 0>;
			};

			pd_ai_sys: ai-sys {
				compatible = "sprd,roc1-npu-power-domain";
				syscons = <&pmu_apb_regs
				REG_PMU_APB_PD_AI_SYS_CFG
				MASK_PMU_APB_PD_AI_SYS_FORCE_SHUTDOWN>;
				syscon-names = "cfg";
			};

			pd_ai_powervr: power-vr {
				compatible = "sprd,roc1-npu-power-domain";
				syscons = <&pmu_apb_regs
				REG_PMU_APB_PD_AI_POWERVR_CFG
				MASK_PMU_APB_PD_AI_POWERVR_FORCE_SHUTDOWN>;
				syscon-names = "cfg";
				sprd,pd-ai = <&pd_ai_sys>;
			};

			pd_ai_cambricon: cambricon-1h {
				compatible = "sprd,roc1-npu-power-domain";
				syscons = <&pmu_apb_regs
				REG_PMU_APB_PD_AI_CAMBRICON_CFG
				MASK_PMU_APB_PD_AI_CAMBRICON_FORCE_SHUTDOWN>;
				syscon-names = "cfg";
				sprd,pd-ai = <&pd_ai_sys>;
			};

			pd_ipa_sys: sipa-sys {
				compatible = "sprd,roc1-ipa-sys-power-domain";
				syscons = <&pmu_apb_regs
					  REG_PMU_APB_IPA_FORCE_WAKEUP_CFG
					  MASK_PMU_APB_IPA_FORCE_WAKEUP>,
					  <&pmu_apb_regs
					  REG_PMU_APB_PD_IPA_SYS_CFG
					  MASK_PMU_APB_PD_IPA_SYS_FORCE_SHUTDOWN>,
					  <&pmu_apb_regs
					  REG_PMU_APB_PD_IPA_SYS_CFG
					  MASK_PMU_APB_PD_IPA_SYS_AUTO_SHUTDOWN_EN>,
					  <&pmu_apb_regs
					  REG_PMU_APB_FORCE_DEEP_SLEEP_CFG
					  MASK_PMU_APB_IPA_FORCE_DEEP_SLEEP>,
					  <&pmu_apb_regs
					  REG_PMU_APB_IPA_DSLP_ENA
					  MASK_PMU_APB_IPA_DSLP_ENA>,
					  <&pmu_apb_regs
					  REG_PMU_APB_FORCE_LIGHT_SLEEP_CFG
					  MASK_PMU_APB_IPA_FORCE_LIGHT_SLEEP>,
					  <&pmu_apb_regs
					  REG_PMU_APB_LIGHT_SLEEP_ENABLE
					  MASK_PMU_APB_IPA_LSLP_ENA>,
					  <&pmu_apb_regs
					  REG_PMU_APB_LIGHT_SLEEP_ENABLE
					  MASK_PMU_APB_IPA_SMART_LSLP_ENA>,
					  <&ipa_ahb_regs
					  REG_IPA_AHB_IPA_EB
					  MASK_IPA_AHB_IPA_EB>,
					  <&ipa_ahb_regs
					  REG_IPA_AHB_IPA_EB
					  MASK_IPA_AHB_CM4_EB>,
					  <&ipa_ahb_regs
					  REG_IPA_AHB_MAIN_MTX_LPC
					  MASK_REG_FW0_IPA_S3_LPC_RD_SEC>,
					  <&ipa_ahb_regs
					  REG_IPA_AHB_S5_LPC
					  MASK_REG_FW0_IPA_S3_LPC_WR_SEC>,
					  <&pmu_apb_regs
					  REG_PMU_APB_PWR_STATUS0_DBG
					  MASK_PMU_APB_PD_IPA_SYS_STATE>;

				syscon-names =
					"ipa-sys-forcewakeup",
					"ipa-sys-forceshutdown",
					"ipa-sys-autoshutdown",
					"ipa-sys-forcedslp",
					"ipa-sys-dslpen",
					"ipa-sys-forcelslp",
					"ipa-sys-lslpen",
					"ipa-sys-smartlslpen",
					"ipa-sys-ipaeb",
					"ipa-sys-cm4eb",
					"ipa-sys-autogaten",
					"ipa-sys-s5-autogaten",
					"ipa-sys-pwr-state";
				#power-domain-cells = <0>;

				clocks = <&ipa_clk CLK_IPA_CORE>,
					<&g12_pll CLK_LPLL_409M6>,
					<&ext_26m>;
				clock-names = "ipa_core", "ipa_core_source",
					      "ipa_core_default";
			};
		};

